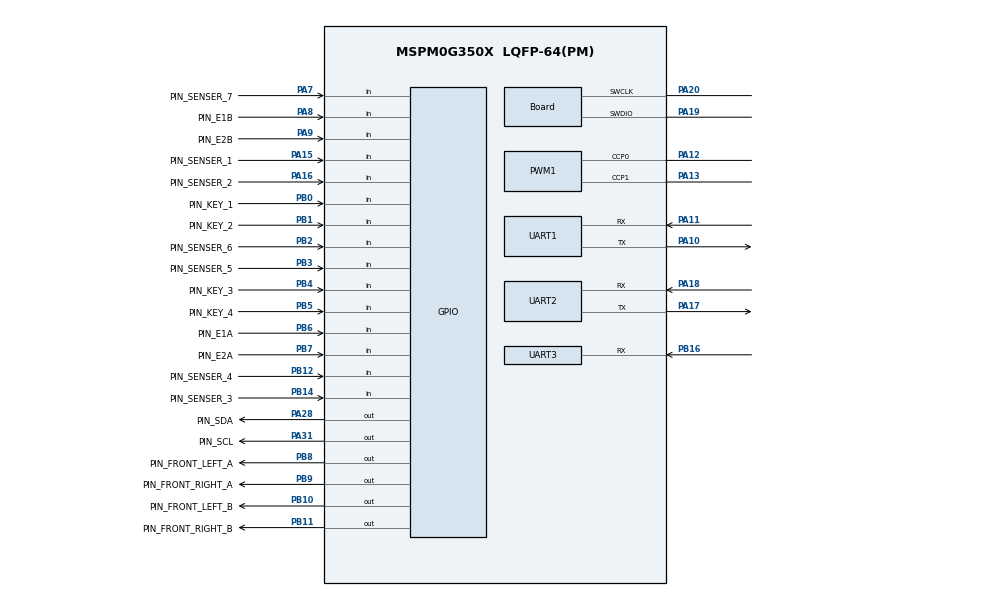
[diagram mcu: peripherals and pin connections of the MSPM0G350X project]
/**
 * @cliArgs --device "MSPM0G350X" --part "Default" --package "LQFP-64(PM)" --product "mspm0_sdk@2.05.00.05"
 * @versions {"tool":"1.24.1+4189"}
 */

/**
 * Import the modules used in this configuration.
 */
const ADC12         = scripting.addModule("/ti/driverlib/ADC12", {}, false);
const ADC121        = ADC12.addInstance();
const GPIO          = scripting.addModule("/ti/driverlib/GPIO", {}, false);
const GPIO1         = GPIO.addInstance();
const GPIO2         = GPIO.addInstance();
const GPIO3         = GPIO.addInstance();
const GPIO4         = GPIO.addInstance();
const GPIO5         = GPIO.addInstance();
const PWM           = scripting.addModule("/ti/driverlib/PWM", {}, false);
const PWM1          = PWM.addInstance();
const SYSCTL        = scripting.addModule("/ti/driverlib/SYSCTL");
const SYSTICK       = scripting.addModule("/ti/driverlib/SYSTICK");
const TIMER         = scripting.addModule("/ti/driverlib/TIMER", {}, false);
const TIMER1        = TIMER.addInstance();
const UART          = scripting.addModule("/ti/driverlib/UART", {}, false);
const UART1         = UART.addInstance();
const UART2         = UART.addInstance();
const UART3         = UART.addInstance();
const ProjectConfig = scripting.addModule("/ti/project_config/ProjectConfig");

/**
 * Write custom configuration values to the imported modules.
 */
ADC121.$name                             = "ADC_VOLTAGE";
ADC121.repeatMode                        = true;
ADC121.peripheral.$assign                = "ADC0";
ADC121.peripheral.adcPin0.$assign        = "PA27";
ADC121.adcPin0Config.hideOutputInversion = scripting.forceWrite(false);
ADC121.adcPin0Config.$name               = "ti_driverlib_gpio_GPIOPinGeneric8";

const Board                       = scripting.addModule("/ti/driverlib/Board", {}, false);
Board.peripheral.$assign          = "DEBUGSS";
Board.peripheral.swclkPin.$assign = "PA20";
Board.peripheral.swdioPin.$assign = "PA19";

GPIO1.$name                         = "GPIO_GRP_MISC";
GPIO1.associatedPins.create(4);
GPIO1.associatedPins[0].$name       = "PIN_KEY_1";
GPIO1.associatedPins[0].direction   = "INPUT";
GPIO1.associatedPins[0].assignedPin = "0";
GPIO1.associatedPins[0].pin.$assign = "PB0";
GPIO1.associatedPins[1].$name       = "PIN_KEY_2";
GPIO1.associatedPins[1].direction   = "INPUT";
GPIO1.associatedPins[1].assignedPin = "1";
GPIO1.associatedPins[1].pin.$assign = "PB1";
GPIO1.associatedPins[2].$name       = "PIN_KEY_3";
GPIO1.associatedPins[2].direction   = "INPUT";
GPIO1.associatedPins[2].pin.$assign = "PB4";
GPIO1.associatedPins[3].$name       = "PIN_KEY_4";
GPIO1.associatedPins[3].direction   = "INPUT";
GPIO1.associatedPins[3].pin.$assign = "PB5";

GPIO2.$name                          = "GPIO_GRP_MOTOR";
GPIO2.associatedPins.create(4);
GPIO2.associatedPins[0].interruptEn  = true;
GPIO2.associatedPins[0].polarity     = "RISE";
GPIO2.associatedPins[0].assignedPort = "PORTB";
GPIO2.associatedPins[0].$name        = "PIN_FRONT_LEFT_A";
GPIO2.associatedPins[0].assignedPin  = "8";
GPIO2.associatedPins[0].pin.$assign  = "PB8";
GPIO2.associatedPins[1].interruptEn  = true;
GPIO2.associatedPins[1].polarity     = "RISE";
GPIO2.associatedPins[1].$name        = "PIN_FRONT_RIGHT_A";
GPIO2.associatedPins[1].assignedPin  = "9";
GPIO2.associatedPins[1].pin.$assign  = "PB9";
GPIO2.associatedPins[2].$name        = "PIN_FRONT_LEFT_B";
GPIO2.associatedPins[2].assignedPin  = "10";
GPIO2.associatedPins[2].pin.$assign  = "PB10";
GPIO2.associatedPins[3].$name        = "PIN_FRONT_RIGHT_B";
GPIO2.associatedPins[3].assignedPin  = "11";
GPIO2.associatedPins[3].pin.$assign  = "PB11";

GPIO3.$name                         = "GPIO_GRP_ENCODER";
GPIO3.associatedPins.create(4);
GPIO3.associatedPins[0].direction   = "INPUT";
GPIO3.associatedPins[0].interruptEn = true;
GPIO3.associatedPins[0].polarity    = "RISE";
GPIO3.associatedPins[0].assignedPin = "6";
GPIO3.associatedPins[0].$name       = "PIN_E1A";
GPIO3.associatedPins[0].pin.$assign = "PB6";
GPIO3.associatedPins[1].direction   = "INPUT";
GPIO3.associatedPins[1].assignedPin = "8";
GPIO3.associatedPins[1].$name       = "PIN_E1B";
GPIO3.associatedPins[1].pin.$assign = "PA8";
GPIO3.associatedPins[2].direction   = "INPUT";
GPIO3.associatedPins[2].interruptEn = true;
GPIO3.associatedPins[2].polarity    = "RISE";
GPIO3.associatedPins[2].assignedPin = "7";
GPIO3.associatedPins[2].$name       = "PIN_E2A";
GPIO3.associatedPins[2].pin.$assign = "PB7";
GPIO3.associatedPins[3].direction   = "INPUT";
GPIO3.associatedPins[3].assignedPin = "9";
GPIO3.associatedPins[3].$name       = "PIN_E2B";
GPIO3.associatedPins[3].pin.$assign = "PA9";

GPIO4.$name                              = "GPIO_GRP_GRAY";
GPIO4.associatedPins.create(7);
GPIO4.associatedPins[0].$name            = "PIN_SENSER_1";
GPIO4.associatedPins[0].direction        = "INPUT";
GPIO4.associatedPins[0].internalResistor = "PULL_UP";
GPIO4.associatedPins[0].pin.$assign      = "PA15";
GPIO4.associatedPins[1].$name            = "PIN_SENSER_2";
GPIO4.associatedPins[1].direction        = "INPUT";
GPIO4.associatedPins[1].internalResistor = "PULL_UP";
GPIO4.associatedPins[1].pin.$assign      = "PA16";
GPIO4.associatedPins[2].$name            = "PIN_SENSER_3";
GPIO4.associatedPins[2].direction        = "INPUT";
GPIO4.associatedPins[2].internalResistor = "PULL_UP";
GPIO4.associatedPins[2].pin.$assign      = "PB14";
GPIO4.associatedPins[3].$name            = "PIN_SENSER_4";
GPIO4.associatedPins[3].direction        = "INPUT";
GPIO4.associatedPins[3].internalResistor = "PULL_UP";
GPIO4.associatedPins[3].pin.$assign      = "PB12";
GPIO4.associatedPins[4].$name            = "PIN_SENSER_5";
GPIO4.associatedPins[4].direction        = "INPUT";
GPIO4.associatedPins[4].internalResistor = "PULL_UP";
GPIO4.associatedPins[4].pin.$assign      = "PB3";
GPIO4.associatedPins[5].$name            = "PIN_SENSER_6";
GPIO4.associatedPins[5].direction        = "INPUT";
GPIO4.associatedPins[5].pin.$assign      = "PB2";
GPIO4.associatedPins[6].$name            = "PIN_SENSER_7";
GPIO4.associatedPins[6].direction        = "INPUT";
GPIO4.associatedPins[6].pin.$assign      = "PA7";

GPIO5.$name                         = "GPIO_GRP_OLED";
GPIO5.associatedPins.create(2);
GPIO5.associatedPins[0].$name       = "PIN_SCL";
GPIO5.associatedPins[0].pin.$assign = "PA31";
GPIO5.associatedPins[1].$name       = "PIN_SDA";
GPIO5.associatedPins[1].pin.$assign = "PA28";

PWM1.$name                              = "PWM_FRONT_MOTOR";
PWM1.pwmMode                            = "EDGE_ALIGN_UP";
PWM1.timerCount                         = 10000;
PWM1.peripheral.$assign                 = "TIMG0";
PWM1.peripheral.ccp0Pin.$assign         = "PA12";
PWM1.peripheral.ccp1Pin.$assign         = "PA13";
PWM1.PWM_CHANNEL_0.$name                = "ti_driverlib_pwm_PWMTimerCC0";
PWM1.PWM_CHANNEL_1.$name                = "ti_driverlib_pwm_PWMTimerCC1";
PWM1.ccp0PinConfig.direction            = scripting.forceWrite("OUTPUT");
PWM1.ccp0PinConfig.hideOutputInversion  = scripting.forceWrite(false);
PWM1.ccp0PinConfig.onlyInternalResistor = scripting.forceWrite(false);
PWM1.ccp0PinConfig.passedPeripheralType = scripting.forceWrite("Digital");
PWM1.ccp0PinConfig.$name                = "ti_driverlib_gpio_GPIOPinGeneric2";
PWM1.ccp1PinConfig.direction            = scripting.forceWrite("OUTPUT");
PWM1.ccp1PinConfig.hideOutputInversion  = scripting.forceWrite(false);
PWM1.ccp1PinConfig.onlyInternalResistor = scripting.forceWrite(false);
PWM1.ccp1PinConfig.passedPeripheralType = scripting.forceWrite("Digital");
PWM1.ccp1PinConfig.$name                = "ti_driverlib_gpio_GPIOPinGeneric3";

SYSCTL.clockTreeEn = true;

SYSTICK.periodEnable    = true;
SYSTICK.period          = 32000;
SYSTICK.interruptEnable = true;

TIMER1.$name              = "TIMER_0";
TIMER1.timerClkDiv        = 2;
TIMER1.timerMode          = "PERIODIC";
TIMER1.interrupts         = ["ZERO"];
TIMER1.timerClkPrescale   = 16;
TIMER1.timerPeriod        = "50 ms";
TIMER1.peripheral.$assign = "TIMA0";

UART1.$name                            = "UART_DEBUG";
UART1.targetBaudRate                   = 115200;
UART1.rxFifoThreshold                  = "DL_UART_RX_FIFO_LEVEL_ONE_ENTRY";
UART1.enableDMARX                      = false;
UART1.enableDMATX                      = false;
UART1.enabledInterrupts                = ["RX"];
UART1.peripheral.$assign               = "UART0";
UART1.peripheral.rxPin.$assign         = "PA11";
UART1.peripheral.txPin.$assign         = "PA10";
UART1.txPinConfig.direction            = scripting.forceWrite("OUTPUT");
UART1.txPinConfig.hideOutputInversion  = scripting.forceWrite(false);
UART1.txPinConfig.onlyInternalResistor = scripting.forceWrite(false);
UART1.txPinConfig.passedPeripheralType = scripting.forceWrite("Digital");
UART1.txPinConfig.$name                = "ti_driverlib_gpio_GPIOPinGeneric0";
UART1.rxPinConfig.hideOutputInversion  = scripting.forceWrite(false);
UART1.rxPinConfig.onlyInternalResistor = scripting.forceWrite(false);
UART1.rxPinConfig.passedPeripheralType = scripting.forceWrite("Digital");
UART1.rxPinConfig.$name                = "ti_driverlib_gpio_GPIOPinGeneric1";

UART2.enabledInterrupts                = ["RX"];
UART2.$name                            = "UART_Camera";
UART2.targetBaudRate                   = 115200;
UART2.peripheral.$assign               = "UART1";
UART2.peripheral.rxPin.$assign         = "PA18";
UART2.peripheral.txPin.$assign         = "PA17";
UART2.txPinConfig.direction            = scripting.forceWrite("OUTPUT");
UART2.txPinConfig.hideOutputInversion  = scripting.forceWrite(false);
UART2.txPinConfig.onlyInternalResistor = scripting.forceWrite(false);
UART2.txPinConfig.passedPeripheralType = scripting.forceWrite("Digital");
UART2.txPinConfig.$name                = "ti_driverlib_gpio_GPIOPinGeneric6";
UART2.rxPinConfig.hideOutputInversion  = scripting.forceWrite(false);
UART2.rxPinConfig.onlyInternalResistor = scripting.forceWrite(false);
UART2.rxPinConfig.passedPeripheralType = scripting.forceWrite("Digital");
UART2.rxPinConfig.$name                = "ti_driverlib_gpio_GPIOPinGeneric7";

UART3.$name                            = "UART_WIT";
UART3.targetBaudRate                   = 115200;
UART3.direction                        = "RX";
UART3.enableFIFO                       = true;
UART3.rxTimeoutValue                   = 1;
UART3.enabledInterrupts                = ["RX_TIMEOUT_ERROR"];
UART3.enabledDMARXTriggers             = "DL_UART_DMA_INTERRUPT_RX";
UART3.rxPinConfig.hideOutputInversion  = scripting.forceWrite(false);
UART3.rxPinConfig.onlyInternalResistor = scripting.forceWrite(false);
UART3.rxPinConfig.passedPeripheralType = scripting.forceWrite("Digital");
UART3.rxPinConfig.$name                = "ti_driverlib_gpio_GPIOPinGeneric5";
UART3.peripheral.$assign               = "UART2";
UART3.peripheral.rxPin.$assign         = "PB16";
UART3.DMA_CHANNEL_RX.addressMode       = "f2b";
UART3.DMA_CHANNEL_RX.srcLength         = "BYTE";
UART3.DMA_CHANNEL_RX.dstLength         = "BYTE";
UART3.DMA_CHANNEL_RX.$name             = "DMA_WIT";

ProjectConfig.deviceSpin = "MSPM0G3507";

/**
 * Pinmux solution for unlocked pins/peripherals. This ensures that minor changes to the automatic solver in a future
 * version of the tool will not impact the pinmux you originally saw.  These lines can be completely deleted in order to
 * re-solve from scratch.
 */
UART3.DMA_CHANNEL_RX.peripheral.$suggestSolution = "DMA_CH0";
